# LargeDummyDevice register map
File version: 1.0
Registers are 32-bit, read-write, no defined reset value unless marked. A register's access mark holds for its fields unless they carry their own. Offsets are from the block's base; [hi:lo] are bit positions.

## PERIPHERAL_6
Base 0x40005000
0x04 REG_1 — Register 1
  [32:30] FIELD_3, [33:30] FIELD_17, [33:30] FIELD_18, [33:30] FIELD_29, [32:29] FIELD_10, [28:27] FIELD_9, [27] FIELD_26, [26] FIELD_15, [28:26] FIELD_25, [26:23] FIELD_19, [20:19] FIELD_5, [22:18] FIELD_7, [16] FIELD_6, [18:15] FIELD_2, [16:15] FIELD_16, [14] FIELD_22, [14:13] FIELD_1, [16:12] FIELD_21, [13:11] FIELD_24, [12:11] FIELD_28, [10] FIELD_20, [13:9] FIELD_12, [10:8] FIELD_11, [10:7] FIELD_14, [7:6] FIELD_4, [6:5] FIELD_30, [5:3] FIELD_27, [4:2] FIELD_13, [5:2] FIELD_31, [3:0] FIELD_8, [0] FIELD_23
0x08 REG_2 — Register 2
  [22] FIELD_5, [21] FIELD_2, [24:20] FIELD_1, [17:14] FIELD_4, [9] FIELD_3
0x0C REG_3 — Register 3
  [31:30] FIELD_12, [29] FIELD_21, [31:28] FIELD_26, [31:27] FIELD_3, [30:26] FIELD_14, [28:25] FIELD_29, [22:21] FIELD_6, [22:20] FIELD_15, [22:18] FIELD_7, [21:18] FIELD_23, [17] FIELD_4, [18:17] FIELD_11, [20:16] FIELD_9, [19:16] FIELD_13, [18:16] FIELD_25, [19:16] FIELD_30, [20:16] FIELD_31, [18:14] FIELD_24, [16:12] FIELD_32, [13:11] FIELD_1, [11] FIELD_17, [13:11] FIELD_20, [12:10] FIELD_10, [12:10] FIELD_22, [12:8] FIELD_18, [7] FIELD_19, [8:6] FIELD_2, [7:6] FIELD_27, [7:5] FIELD_8, [8:4] FIELD_28, [5:3] FIELD_5, [3:2] FIELD_16
0x10 REG_4 — Register 4
  [34:31] FIELD_20, [31:30] FIELD_13, [31:29] FIELD_2, [28:27] FIELD_12, [26:24] FIELD_17, [24:23] FIELD_1, [27:23] FIELD_8, [22:20] FIELD_14, [17:13] FIELD_4, [14:13] FIELD_10, [16:13] FIELD_15, [15:12] FIELD_5, [12] FIELD_9, [12] FIELD_11, [10:9] FIELD_18, [9:6] FIELD_3, [8:6] FIELD_19, [7:5] FIELD_7, [5:3] FIELD_16, [3:2] FIELD_6
0x14 REG_5 — Register 5
  [27] FIELD_3, [19:18] FIELD_5, [20:16] FIELD_1, [19:16] FIELD_2, [2:1] FIELD_4

## PERIPHERAL_11
Base 0x4000A000
0x04 REG_1 — Register 1
  [35:31] FIELD_1, [35:31] FIELD_7, [32:30] FIELD_15, [34:30] FIELD_16, [30:28] FIELD_3, [30:28] FIELD_10, [30:26] FIELD_9, [27:24] FIELD_6, [26:24] FIELD_13, [19] FIELD_4, [21:19] FIELD_8, [19] FIELD_19, [20:17] FIELD_2, [15:12] FIELD_12, [15:11] FIELD_17, [12:8] FIELD_18, [5:4] FIELD_5, [4:2] FIELD_11, [3:1] FIELD_14
0x08 REG_2 — Register 2
  [32:31] FIELD_2, [33:30] FIELD_16, [33:29] FIELD_28, [29:26] FIELD_19, [28:25] FIELD_3, [26:25] FIELD_8, [27:25] FIELD_11, [25:24] FIELD_12, [27:24] FIELD_21, [23:21] FIELD_4, [24:21] FIELD_14, [24:21] FIELD_18, [23:19] FIELD_7, [20:19] FIELD_20, [22:18] FIELD_23, [18:16] FIELD_5, [17:14] FIELD_17, [16:14] FIELD_24, [16:13] FIELD_15, [15:12] FIELD_10, [14:11] FIELD_25, [14:10] FIELD_22, [12:9] FIELD_26, [10:9] FIELD_29, [8:6] FIELD_13, [6:5] FIELD_27, [6:3] FIELD_6, [4:1] FIELD_1, [5:1] FIELD_9
0x0C REG_3 — Register 3
  [31] FIELD_2, [34:31] FIELD_12, [31:29] FIELD_7, [28] FIELD_18, [29:27] FIELD_11, [29:26] FIELD_3, [27:24] FIELD_16, [27:23] FIELD_8, [23] FIELD_15, [24:23] FIELD_20, [26:22] FIELD_21, [23:19] FIELD_17, [21:17] FIELD_1, [16:15] FIELD_4, [16:14] FIELD_6, [13:12] FIELD_10, [12:11] FIELD_13, [14:10] FIELD_14, [9:8] FIELD_9, [9:8] FIELD_22, [6:3] FIELD_5, [5:3] FIELD_19
0x10 REG_4 — Register 4
  [34:31] FIELD_20, [30] FIELD_25, [30:29] FIELD_24, [29:26] FIELD_12, [29:25] FIELD_19, [24:22] FIELD_10, [22:19] FIELD_13, [17:16] FIELD_4, [16] FIELD_6, [18:15] FIELD_16, [14:13] FIELD_23, [14:12] FIELD_1, [13:12] FIELD_7, [13:12] FIELD_8, [16:12] FIELD_14, [14:10] FIELD_2, [12:10] FIELD_9, [13:10] FIELD_26, [11:9] FIELD_11, [5] FIELD_15, [5] FIELD_22, [3] FIELD_3, [4:3] FIELD_17, [6:2] FIELD_5, [0] FIELD_18, [4:0] FIELD_21
0x14 REG_5 — Register 5
  [27:24] FIELD_3, [25:24] FIELD_7, [24:21] FIELD_2, [19:18] FIELD_5, [5:2] FIELD_1, [1:0] FIELD_4, [3:0] FIELD_6

## PERIPHERAL_15
Base 0x4000E000
0x04 REG_1 — Register 1
  [22:21] FIELD_5, [9:7] FIELD_3, [7] FIELD_4, [7:6] FIELD_1, [4:3] FIELD_2
0x08 REG_2 — Register 2
  [33:31] FIELD_22, [33:30] FIELD_11, [28:27] FIELD_15, [27:26] FIELD_10, [25] FIELD_20, [25:24] FIELD_18, [26:23] FIELD_12, [19] FIELD_1, [23:19] FIELD_5, [19] FIELD_6, [19:17] FIELD_23, [15] FIELD_9, [14] FIELD_13, [13] FIELD_19, [8] FIELD_14, [8:7] FIELD_8, [8:6] FIELD_2, [9:6] FIELD_7, [8:5] FIELD_17, [5:2] FIELD_4, [4:2] FIELD_16, [3:1] FIELD_3, [1:0] FIELD_21
0x0C REG_3 — Register 3
  [30] FIELD_20, [31:30] FIELD_24, [31:28] FIELD_6, [30:27] FIELD_1, [29:27] FIELD_25, [30:26] FIELD_22, [26:25] FIELD_4, [27:24] FIELD_11, [24:23] FIELD_12, [23] FIELD_16, [24:22] FIELD_2, [22:21] FIELD_5, [25:21] FIELD_10, [23:20] FIELD_9, [21:20] FIELD_15, [22:18] FIELD_18, [17] FIELD_14, [16] FIELD_8, [14] FIELD_19, [17:14] FIELD_23, [15:13] FIELD_26, [10:7] FIELD_13, [9:7] FIELD_17, [5:4] FIELD_7, [4:2] FIELD_21, [3:0] FIELD_3
0x10 REG_4 — Register 4
  [16:14] FIELD_1, [18:14] FIELD_2, [4:0] FIELD_3
0x14 REG_5 — Register 5
  [30:29] FIELD_8, [31:28] FIELD_7, [28:27] FIELD_6, [26:25] FIELD_13, [24] FIELD_3, [27:23] FIELD_16, [24:21] FIELD_10, [20:19] FIELD_1, [21:18] FIELD_4, [14] FIELD_5, [11] FIELD_12, [12:10] FIELD_19, [11:9] FIELD_15, [10:8] FIELD_18, [10:7] FIELD_17, [8:5] FIELD_2, [9:5] FIELD_14, [3] FIELD_9, [2:1] FIELD_11
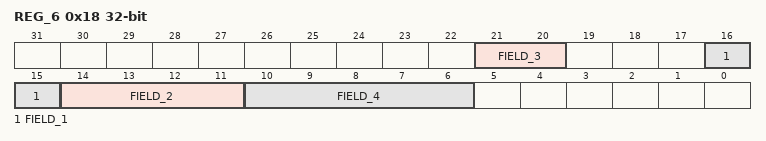
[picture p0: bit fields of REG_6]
0x18 REG_6 — Register 6
  [21:20] FIELD_3, [16:15] FIELD_1, [14:11] FIELD_2, [10:6] FIELD_4
0x1C REG_7 — Register 7
  [33:29] FIELD_13, [26:25] FIELD_7, [26:24] FIELD_4, [23:22] FIELD_8, [21] FIELD_1, [20:18] FIELD_12, [21:17] FIELD_9, [20:17] FIELD_14, [14:12] FIELD_6, [15:11] FIELD_5, [11:9] FIELD_10, [8:7] FIELD_2, [6] FIELD_11, [4:3] FIELD_3
0x20 REG_8 — Register 8
  [30] FIELD_12, [26:25] FIELD_2, [27:24] FIELD_6, [23] FIELD_1, [24:22] FIELD_14, [23:19] FIELD_4, [22:19] FIELD_7, [19:17] FIELD_17, [18:15] FIELD_11, [14:13] FIELD_3, [15:12] FIELD_15, [14:11] FIELD_10, [12:9] FIELD_8, [8:5] FIELD_9, [5:4] FIELD_13, [6:4] FIELD_16, [1] FIELD_5
0x24 REG_9 — Register 9
  [27:25] FIELD_5, [27:24] FIELD_2, [21:19] FIELD_6, [20:19] FIELD_9, [13:11] FIELD_7, [13:10] FIELD_4, [12:9] FIELD_1, [8] FIELD_3, [8:4] FIELD_10, [4:1] FIELD_8
0x28 REG_10 — Register 10
  [32:29] FIELD_5, [32:28] FIELD_3, [22:21] FIELD_6, [16:12] FIELD_1, [12:11] FIELD_4, [7:6] FIELD_7, [9:5] FIELD_2
0x2C REG_11 — Register 11
  [25] FIELD_11, [27:24] FIELD_5, [26:23] FIELD_3, [25:21] FIELD_7, [22:21] FIELD_9, [25:21] FIELD_12, [22:20] FIELD_6, [20] FIELD_8, [18:17] FIELD_1, [11:8] FIELD_2, [11:8] FIELD_4, [7] FIELD_13, [11:7] FIELD_14, [0] FIELD_10
0x30 REG_12 — Register 12
  [32:31] FIELD_5, [13] FIELD_4, [11:8] FIELD_3, [8:5] FIELD_2, [7:3] FIELD_1
0x34 REG_13 — Register 13
  [34:31] FIELD_29, [31:29] FIELD_3, [29] FIELD_5, [29] FIELD_19, [29:28] FIELD_20, [26] FIELD_4, [30:26] FIELD_16, [25] FIELD_27, [28:24] FIELD_9, [26:24] FIELD_13, [24:22] FIELD_7, [24:22] FIELD_30, [20] FIELD_11, [20] FIELD_18, [19] FIELD_26, [19:18] FIELD_21, [21:17] FIELD_14, [18:16] FIELD_6, [19:16] FIELD_24, [18:15] FIELD_1, [17:14] FIELD_28, [13:12] FIELD_15, [15:12] FIELD_25, [15:11] FIELD_2, [15:11] FIELD_22, [10:8] FIELD_8, [7:6] FIELD_10, [6] FIELD_17, [7:3] FIELD_23, [4:2] FIELD_12
0x38 REG_14 — Register 14
  [33:31] FIELD_5, [30:29] FIELD_1, [30:27] FIELD_17, [28:25] FIELD_4, [25:22] FIELD_14, [20] FIELD_12, [18:16] FIELD_10, [18:14] FIELD_9, [13] FIELD_3, [15:13] FIELD_15, [15:13] FIELD_16, [13:10] FIELD_6, [8] FIELD_7, [11:8] FIELD_13, [9:5] FIELD_2, [4] FIELD_8, [2] FIELD_11
